VERSION ""

BO_ 100 Body_Status: 8 BCM
 SG_ VehSpd : 0|16@1+ (0.01,0) [0|220] "km/h" ECM,IC
 SG_ IgnitionState : 16|2@1+ (1,0) [0|3] "" ECM
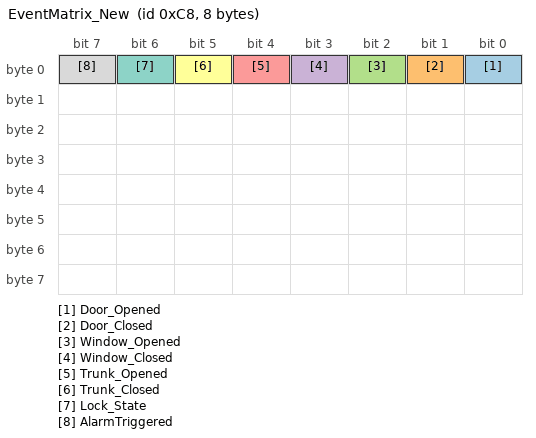
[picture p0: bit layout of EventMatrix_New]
BO_ 200 EventMatrix_New: 8 ECU
 SG_ Door_Opened : 0|1@1+ (1,0) [0|1] "" Gateway
 SG_ Door_Closed : 1|1@1+ (1,0) [0|1] "" Gateway
 SG_ Window_Opened : 2|1@1+ (1,0) [0|1] "" Gateway
 SG_ Window_Closed : 3|1@1+ (1,0) [0|1] "" Gateway
 SG_ Trunk_Opened : 4|1@1+ (1,0) [0|1] "" Gateway
 SG_ Trunk_Closed : 5|1@1+ (1,0) [0|1] "" Gateway
 SG_ Lock_State : 6|1@1+ (1,0) [0|1] "" Gateway
 SG_ AlarmTriggered : 7|1@1+ (1,0) [0|1] "" Gateway
BO_ 300 Engine_Info: 8 ECU
 SG_ EngineRPM : 0|16@1+ (0.5,0) [0|8000] "rpm" ECM
 SG_ CoolantTemp : 16|8@1+ (1,-40) [-40|215] "C" ECM
 SG_ DiagState : 0|8@1+ (1,0) [0|255] "" Vector__XXX
BA_ "GenMsgCycleTime" BO_ 100 10;
